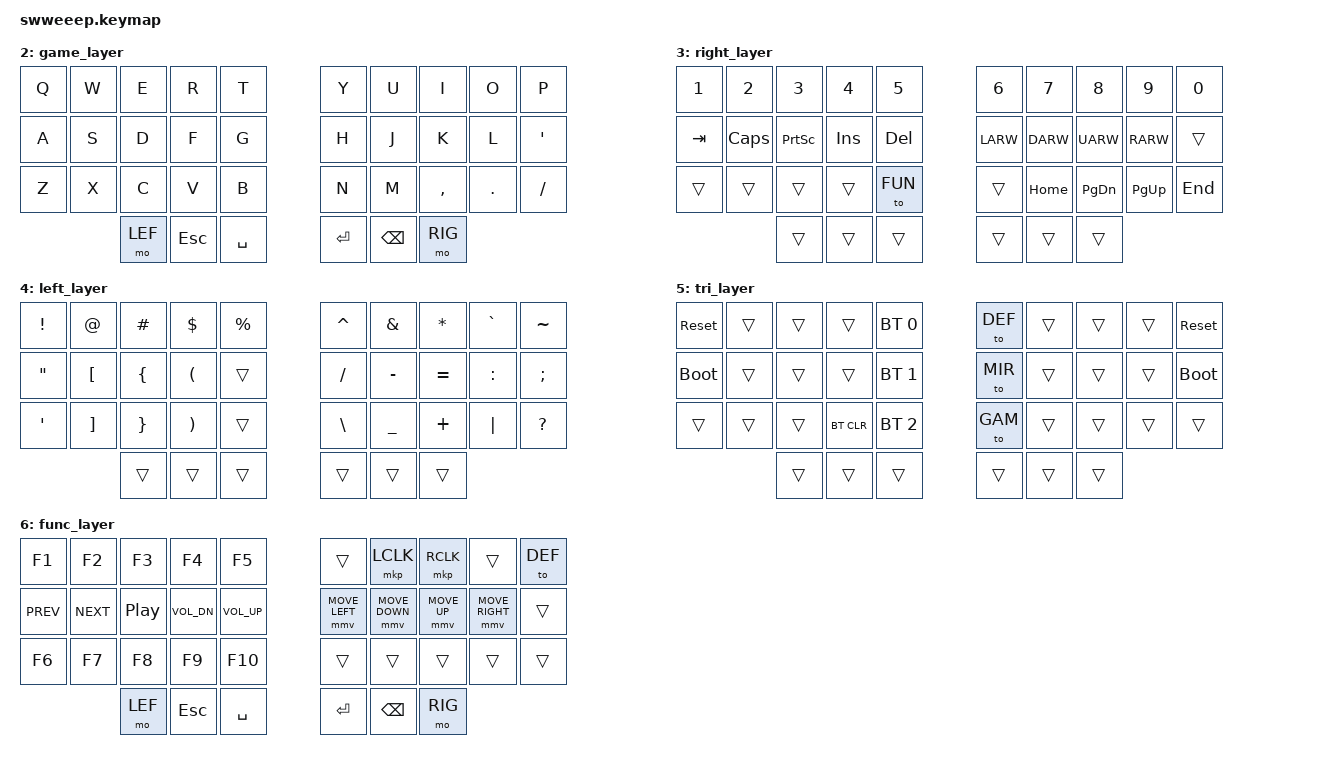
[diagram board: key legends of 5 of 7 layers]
#include <behaviors.dtsi>
#include <dt-bindings/zmk/bt.h>
#include <dt-bindings/zmk/keys.h>
#include <dt-bindings/zmk/mouse.h>
#include <dt-bindings/zmk/outputs.h>
#include <dt-bindings/zmk/ext_power.h>

#define HRML(k1,k2,k3,k4) &ht LGUI k1  &ht LALT k2  &ht LCTRL k3  &ht LSHFT k4
#define HRMR(k1,k2,k3,k4) &ht RSHFT k1  &ht RCTRL k2  &ht RALT k3  &ht RGUI k4

#define DEF 0
#define MIR 1
#define GAM 2
#define RIG 3
#define LEF 4
#define TRI 5
#define FUN 6

&caps_word {
    continue-list = <UNDERSCORE MINUS>;
};

/ {
    combos {
        compatible = "zmk,combos";
        combo_undo {
            timeout-ms = <50>;
            key-positions = <20 21>;
            bindings = <&kp LC(Z)>;
        };
    };
};

/ {

    behaviors {
        ht: homerow_mods {
            label = "hold_tap";
            compatible = "zmk,behavior-hold-tap";
            #binding-cells = <2>;
            tapping-term-ms = <220>;
            quick-tap-ms = <150>;
            global-quick-tap;
            flavor = "tap-preferred";
            bindings = <&kp>, <&kp>;
        };
        td0: tap_dance_0 {
            compatible = "zmk,behavior-tap-dance";
            #binding-cells = <0>;
            tapping-term-ms = <150>;
            bindings = <&kp N1>, <&kp N2>, <&kp N3>;
        };
    };

    conditional_layers {
        compatible = "zmk,conditional-layers";
        tri_layer {
            if-layers = <RIG LEF>;
            then-layer = <TRI>;
        };
    };

   keymap {
        compatible = "zmk,keymap";
        default_layer {
            bindings = <
        //╭──────────┬──────────┬──────────┬──────────┬──────────╮   ╭──────────┬──────────┬──────────┬──────────┬──────────╮
        //│  Q       │  W       │  E       │  R       │  T       │   │  Y       │  U       │  I       │  O       │  P       │
            &kp Q      &kp W      &kp E      &kp R      &kp T          &kp Y      &kp U      &kp I      &kp O      &kp P
        //├──────────┼──────────┼──────────┼──────────┼──────────┤   ├──────────┼──────────┼──────────┼──────────┼──────────┤
        //│  A       │  S       │  D       │  F       │  G       │   │  H       │  J       │  K       │  L       │ ' "      │
            HRML(A,        S,         D,         F)     &kp G          &kp H      HRMR(J,        K,         L,        SQT)
        //├──────────┼──────────┼──────────┼──────────┼──────────┤   ├──────────┼──────────┼──────────┼──────────┼──────────┤
        //│  Z       │  X       │  C       │  V       │  B       │   │  N       │  M       │ , <      │ . >      │ / ?      │
            &kp Z      &kp X      &kp C      &kp V      &kp B          &kp N      &kp M      &kp COMMA  &kp DOT    &kp FSLH
        //╰──────────┴──────────┴──────────┼──────────┼──────────┤   ├──────────┼──────────┼──────────┴──────────┴──────────╯
                                 &mo LEF     &kp ESC    &kp SPACE     &kp ENTER   &kp BSPC   &mo RIG
        //                      ╰──────────┴──────────┴──────────╯   ╰──────────┴──────────┴──────────╯
            >;
        }; 

        miryoku_layer {
            bindings = <
        //╭──────────┬──────────┬──────────┬──────────┬──────────╮   ╭──────────┬──────────┬──────────┬──────────┬──────────╮
        //│  Q       │  W       │  F       │  P       │  B       │   │  J       │  L       │  U       │  Y       │  '       │
            &kp Q      &kp W      &kp F      &kp P      &kp B          &kp J      &kp L      &kp U      &kp Y      &kp SQT
        //├──────────┼──────────┼──────────┼──────────┼──────────┤   ├──────────┼──────────┼──────────┼──────────┼──────────┤
        //│  A       │  R       │  S       │  T       │  G       │   │  M       │  N       │  E       │  I       │ O        │
            HRML(A,        R,         S,         T)     &kp G          &kp M      HRMR(N,        E,         I,        O)
        //├──────────┼──────────┼──────────┼──────────┼──────────┤   ├──────────┼──────────┼──────────┼──────────┼──────────┤
        //│  Z       │  X       │  C       │  D       │  V       │   │  K       │  H       │ , <      │ . >      │ / ?      │
            &kp Z      &kp X      &kp C      &kp D      &kp V          &kp K      &kp H      &kp COMMA  &kp DOT    &kp FSLH
        //╰──────────┴──────────┴──────────┼──────────┼──────────┤   ├──────────┼──────────┼──────────┴──────────┴──────────╯
                                 &mo LEF     &kp ESC    &kp SPACE     &kp ENTER   &kp BSPC   &mo RIG
        //                      ╰──────────┴──────────┴──────────╯   ╰──────────┴──────────┴──────────╯
            >;
        };

        game_layer {
            bindings = <
        //╭──────────┬──────────┬──────────┬──────────┬──────────╮   ╭──────────┬──────────┬──────────┬──────────┬──────────╮
            &kp Q     &kp W     &kp E     &kp R     &kp T           &kp Y     &kp U     &kp I     &kp O     &kp P
        //├──────────┼──────────┼──────────┼──────────┼──────────┤   ├──────────┼──────────┼──────────┼──────────┼──────────┤
            &kp A     &kp S     &kp D     &kp F     &kp G           &kp H     &kp J     &kp K     &kp L     &kp SQT
        //├──────────┼──────────┼──────────┼──────────┼──────────┤   ├──────────┼──────────┼──────────┼──────────┼──────────┤
            &kp Z     &kp X     &kp C     &kp V     &kp B           &kp N     &kp M     &kp COMMA &kp DOT   &kp FSLH
        //╰──────────┴──────────┴──────────┼──────────┼──────────┤   ├──────────┼──────────┼──────────┴──────────┴──────────╯
                                &mo LEF     &kp ESC   &kp SPACE      &kp ENTER  &kp BSPC  &mo RIG
        //                      ╰──────────┴──────────┴──────────╯   ╰──────────┴──────────┴──────────╯
            >;
        };

        right_layer {
            bindings = <
        //╭──────────┬──────────┬──────────┬──────────┬──────────╮   ╭──────────┬──────────┬──────────┬──────────┬──────────╮
        //│ 1        │  2       │  3       │  4       │  5       │   │ 6        │ 7        │ 8        │ 9        │   0      │
            &kp N1    &kp N2     &kp N3     &kp N4     &kp N5          &kp N6     &kp N7     &kp N8     &kp N9      &kp N0
        //├──────────┼──────────┼──────────┼──────────┼──────────┤   ├──────────┼──────────┼──────────┼──────────┼──────────┤
        //│ TAB      │ CapsLock │ PrintSc  │  INSERT  │ DELETE   |   |  LEFT    │ DOWN     │ UP       │ RIGHT    │          │
            &kp TAB   &kp CAPS   &kp PSCRN  &kp INS     &kp DEL        &kp LARW    &kp DARW   &kp UARW   &kp RARW   &trans
        //├──────────┼──────────┼──────────┼──────────┼──────────┤   ├──────────┼──────────┼──────────┼──────────┼──────────┤
        //│          │          │          │          │          │   │          │ HOME     │ PAGE DN  │ PAGE UP  │ END      │
            &trans    &trans     &trans     &trans      &to FUN        &trans     &kp HOME   &kp PG_DN  &kp PG_UP  &kp END
        //╰──────────┴──────────┴──────────┼──────────┼──────────┤   ├──────────┼──────────┼──────────┴──────────┴──────────╯
                                  &trans     &trans     &trans         &trans     &trans     &trans
        //                      ╰──────────┴──────────┴──────────╯   ╰──────────┴──────────┴──────────╯
            >;
        };

        left_layer {
            bindings = <
        //╭──────────┬──────────┬──────────┬──────────┬──────────╮   ╭──────────┬──────────┬──────────┬──────────┬──────────╮
        //│  !       │  @       │  #       │  $       │  %       │   │  ^       │  &       │  *       │  `       │  ~       │
            &kp EXCL   &kp AT     &kp HASH   &kp DLLR   &kp PRCNT      &kp CARET  &kp AMPS   &kp ASTRK  &kp GRAVE   &kp TILDE
        //├──────────┼──────────┼──────────┼──────────┼──────────┤   ├──────────┼──────────┼──────────┼──────────┼──────────┤
        //│  "       │  [       │  {       │  (       │          │   │   /      │  -       │  =       │     :    │  ;       │
            &kp DQT    &kp LBKT   &kp LBRC   &kp LPAR   &trans         &kp FSLH   &kp MINUS  &kp EQUAL  &kp COLON   &kp SEMI
        //├──────────┼──────────┼──────────┼──────────┼──────────┤   ├──────────┼──────────┼──────────┼──────────┼──────────┤
        //│  '       │  ]       │  }       │  )       │          │   │    \     │  _       │  +       │  │       │   ?      │
            &kp SQT     &kp RBKT   &kp RBRC   &kp RPAR   &trans         &kp BSLH   &kp UNDER  &kp PLUS   &kp PIPE  &kp QMARK
        //╰──────────┴──────────┴──────────┼──────────┼──────────┤   ├──────────┼──────────┼──────────┴──────────┴──────────╯
                                  &trans     &trans     &trans         &trans     &trans     &trans
        //                      ╰──────────┴──────────┴──────────╯   ╰──────────┴──────────┴──────────╯
            >;
        };

        tri_layer {
            bindings = <
        //╭──────────┬──────────┬──────────┬──────────┬──────────╮   ╭──────────┬──────────┬──────────┬──────────┬──────────╮
        //│ RESET    │          │          │          │PROFILE 0 │   │ DEFAULT  │          │          │          │  RESET   │
           &sys_reset  &trans     &trans     &trans    &bt BT_SEL 0    &to DEF     &trans    &trans     &trans   &sys_reset
        //├──────────┼──────────┼──────────┼──────────┼──────────┤   ├──────────┼──────────┼──────────┼──────────┼──────────┤
        //│BOOTLOADER│          │          │          │PROFILE 1 │   │ MIRYOKU  │          │          │          │BOOTLOADER│
          &bootloader  &trans     &trans     &trans    &bt BT_SEL 1    &to MIR    &trans     &trans     &trans    &bootloader
        //├──────────┼──────────┼──────────┼──────────┼──────────┤   ├──────────┼──────────┼──────────┼──────────┼──────────┤
        //│          │          │          │ CLEAR BT │PROFILE 2 │   │  GAMING  │          │          │          │          │
            &trans     &trans     &trans    &bt BT_CLR &bt BT_SEL 2    &to GAM    &trans     &trans     &trans     &trans
        //╰──────────┴──────────┴──────────┼──────────┼──────────┤   ├──────────┼──────────┼──────────┴──────────┴──────────╯
                                  &trans     &trans     &trans         &trans     &trans     &trans
        //                      ╰──────────┴──────────┴──────────╯   ╰──────────┴──────────┴──────────╯
            >;
        };

        func_layer {
            bindings = <
        //╭──────────┬──────────┬──────────┬──────────┬──────────╮   ╭──────────┬──────────┬──────────┬──────────┬──────────╮
            &kp F1      &kp F2     &kp F3     &kp F4     &kp F5           &trans   &mkp LCLK  &mkp RCLK    &trans   &to DEF
        //├──────────┼──────────┼──────────┼──────────┼──────────┤   ├──────────┼──────────┼──────────┼──────────┼──────────┤
            &kp C_PREV  &kp C_NEXT  &kp C_PP   &kp C_VOL_DN &kp C_VOL_UP      &mmv MOVE_LEFT &mmv MOVE_DOWN &mmv MOVE_UP   &mmv MOVE_RIGHT &trans
        //├──────────┼──────────┼──────────┼──────────┼──────────┤   ├──────────┼──────────┼──────────┼──────────┼──────────┤
            &kp F6      &kp F7     &kp F8     &kp F9     &kp F10      &trans  &trans  &trans  &trans  &trans   
        //╰──────────┴──────────┴──────────┼──────────┼──────────┤   ├──────────┼──────────┼──────────┴──────────┴──────────╯
                                &mo LEF     &kp ESC   &kp SPACE      &kp ENTER  &kp BSPC  &mo RIG
        //                      ╰──────────┴──────────┴──────────╯   ╰──────────┴──────────┴──────────╯
            >;
        };
    };
};
